# PIC32MX575F256H device description
Architecture: MIPS; Family: PIC32MX; Series: PIC32MX
Registers are 32-bit, read-write, no defined reset value unless marked. A register's access mark holds for its fields unless they carry their own. Offsets are from the block's base; [hi:lo] are bit positions; {n}, {i} and the like mark numbered series; 'fields as' and 'values as' point back to an identical list.

## NVM
Instances: NVM 0x1f80f400 in periph1
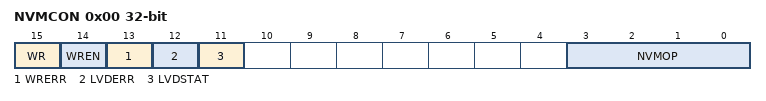
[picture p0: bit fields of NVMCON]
0x00 NVMCON — Programming Control Register
  [15] WR — Write Control bit
    1=Initiate a Flash operation. Hardware clears this bit when the operation completes; 0=Flash operation complete or inactive
  [14] WREN — Write Enable bit
    1=Enable writes to WR bit and enables LVD circuit; 0=Disable writes to WR bit and disables LVD circuit
  [13] WRERR — Write Error bit
    1=Program or erase sequence did not complete successfully; 0=Program or erase sequence completed normally
  [12] LVDERR — Low-Voltage Detect Error bit (LVD circuit must be enabled)
    1=Low-voltage detected (possible data corruption if WRERR is set); 0=Voltage level is acceptable for programming
  [11] LVDSTAT — Low-Voltage Detect Status bit (LVD circuit must be enabled)
    1=Low-voltage event active; 0=Low-voltage event NOT active
  [3:0] NVMOP — NVM Operation bits
    6=No operation; 5=Program Flash (PFM) erase operation: erases PFM if all pages are not write-protected; 4=Page erase operation: erases page selected by NVMADDR if it is not write-protected; 3=Row program operation: programs row selected by NVMADDR if it is not write-protected; 2=No operation; 1=Word program operation: programs word selected by NVMADDR if it is not write-protected; 0=No operation
0x10 NVMKEY wo — Programming Unlock Register
0x20 NVMADDR — Flash Address Register
0x30 NVMDATA
0x40 NVMSRCADDR — Source Data Address Register

## OCMP
Instances: OCMP 0x1f802ff4 in periph0
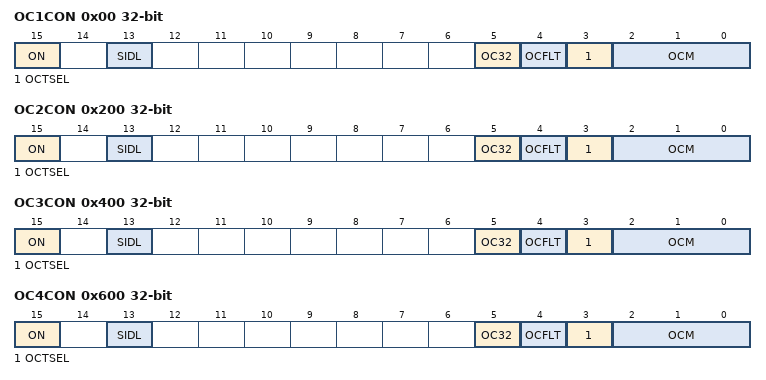
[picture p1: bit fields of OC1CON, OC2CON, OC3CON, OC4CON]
0x00 OC1CON — Output Compare 'x' Control Register
  [15] ON — Output Compare Peripheral On bit
    1=Output Compare peripheral is enabled; 0=Output Compare peripheral is disabled
  [13] SIDL — Stop in Idle Mode bit
    1=Discontinue operation when CPU enters Idle mode; 0=Continue operation in Idle mode
  [5] OC32 — 32-bit Compare Mode bit
    1=OCxR(31-0) and/or OCxRS(31-0) are used for comparisions to the 32-bit timer source; 0=OCxR(15-0) and OCxRS(15-0) are used for comparisons to the 16-bit timer source
  [4] OCFLT — PWM Fault Condition Status bit
    1=PWM Fault condition has occurred (cleared in HW only); 0=No PWM Fault condition has occurred
  [3] OCTSEL — Output Compare Timer Select bit
    1=Timer3 is the clock source for this Output Compare module; 0=Timer2 is the clock source for this Output Compare module
  [2:0] OCM — Output Compare Mode Select bits
    7=PWM mode on OCx; Fault pin enabled; 6=PWM mode on OCx; Fault pin disabled; 5=Initialize OCx pin low; generate continious output pulses on OCx pin; 4=Initialize OCx pin low: generate single output pulse on OCx pin; 3=Compare event toggles OCx pin; 2=Initialize OCx pin high; compare event forces OCx pin low; 1=Initialize OCx pin low; compare event forces OCx pin high; 0=Output compare peripheral is disabled but continues to draw current
0x10 OC1R
0x20 OC1RS
0x200 OC2CON — Output Compare 'x' Control Register
  fields as OC1CON
0x210 OC2R
0x220 OC2RS
0x400 OC3CON — Output Compare 'x' Control Register
  fields as OC1CON
0x410 OC3R
0x420 OC3RS
0x600 OC4CON — Output Compare 'x' Control Register
  fields as OC1CON
0x610 OC4R
0x620 OC4RS
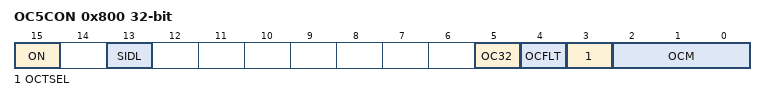
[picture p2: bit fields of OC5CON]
0x800 OC5CON — Output Compare 'x' Control Register
  fields as OC1CON
0x810 OC5R
0x820 OC5RS

## PCACHE
Instances: PCACHE 0x1f884000 in periph2
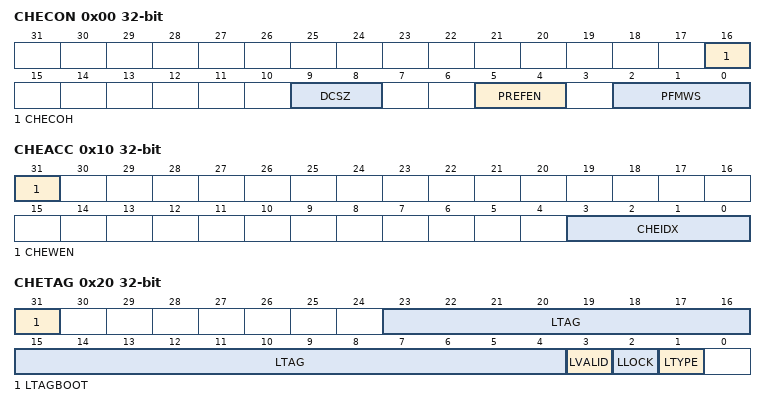
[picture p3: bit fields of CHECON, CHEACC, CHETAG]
0x00 CHECON — Cache Control Register
  [16] CHECOH — Cache Coherency Setting on a PFM Program Cycle bit
    1=Invalidate all data and instruction lines; 0=Invalidate all data lines and instruction lines that are not locked
  [9:8] DCSZ — Data Cache Size in Lines bits
    3=Enable data caching with a size of 4 Lines; 2=Enable data caching with a size of 2 Lines; 1=Enable data caching with a size of 1 Line; 0=Disable data caching
  [5:4] PREFEN — Predictive Prefetch Enable bits
    3=Enable predictive prefetch for both cacheable and non-cacheable regions; 2=Enable predictive prefetch for non-cacheable regions only; 1=Enable predictive prefetch for cacheable regions only; 0=Disable predictive prefetch
  [2:0] PFMWS — PFM Access Time Defined in Terms of SYSLK Wait States bits
    7=Seven Wait states; 6=Six Wait states; 5=Five Wait states; 4=Four Wait states; 3=Three Wait states; 2=Two Wait states; 1=One Wait state; 0=Zero Wait state
0x10 CHEACC — Cache Access Register
  [31] CHEWEN — Cache Access Enable bits for registers CHETAG
    1=The cache line selected by CHEIDX(3:0) is writeable; 0=The cache line selected by CHEIDX(3:0) is not writeable
  [3:0] CHEIDX — Cache Line Index bits
    {v}=Select cache line {v} for reading or writing (v=0..15)
0x20 CHETAG — Cache TAG Register
  [31] LTAGBOOT — Line TAG Address Boot bit
    1=The line is in the 0x1D000000 (physical) area of memory; 0=The line is in the 0x1FC00000 (physical) area of memory
  [23:4] LTAG
  [3] LVALID — Line Valid bit
    1=The line is valid and is compared to the physical address for hit detection; 0=The line is not valid and is not compared to the physical address for hit detection
  [2] LLOCK — Line Lock bit
    1=The line is locked and will not be replaced; 0=The line is not locked and can be replaced
  [1] LTYPE — Line Type bit
    1=The line caches instruction words; 0=The line caches data words
0x30 CHEMSK — Cache TAG Mask Register
  [15:5] LMASK — Line Mask bits
    1=Enables mask logic to force a match on the corresponding bit position in the LTAG(19:0) bits (CHETAG(23:4)) and the physical address; 0=Only writeable for values of CHEIDX(3:0) bits (CHEACC(3:0)) equal to 0x0A and 0x0B. Disables mask logic.
{0x40+0x10*i} CHEW{i} (i=0..3) — Cache Word {i}
0x80 CHELRU — Cache LRU Register
  [24:0] CHELRU
0x90 CHEHIT ro — Cache Hit Statistics Register
0xA0 CHEMIS ro — Cache Miss Statistics Register
0xC0 CHEPFABT ro — Prefetch Cache Abort Statistics Register

## Notices in the file
Copyright (c) 2019 Microchip Technology Inc.
SPDX-License-Identifier: Apache-2.0
Licensed under the Apache License, Version 2.0 (the "License");
you may not use this file except in compliance with the License.
You may obtain a copy of the License at
http://www.apache.org/licenses/LICENSE-2.0
Unless required by applicable law or agreed to in writing, software
distributed under the License is distributed on an "AS IS" BASIS,
WITHOUT WARRANTIES OR CONDITIONS OF ANY KIND, either express or implied.
See the License for the specific language governing permissions and
limitations under the License.
